# NV32F100 register map
File version: 1.6
Registers are 32-bit, read-write, reset 0x0 unless marked. A register's access mark holds for its fields unless they carry their own. Offsets are from the block's base; [hi:lo] are bit positions; {n}, {i} and the like mark numbered series; 'fields as' and 'values as' point back to an identical list.

## SIM — System Integration Module
Base 0x40047000; register names take the prefix SIM_
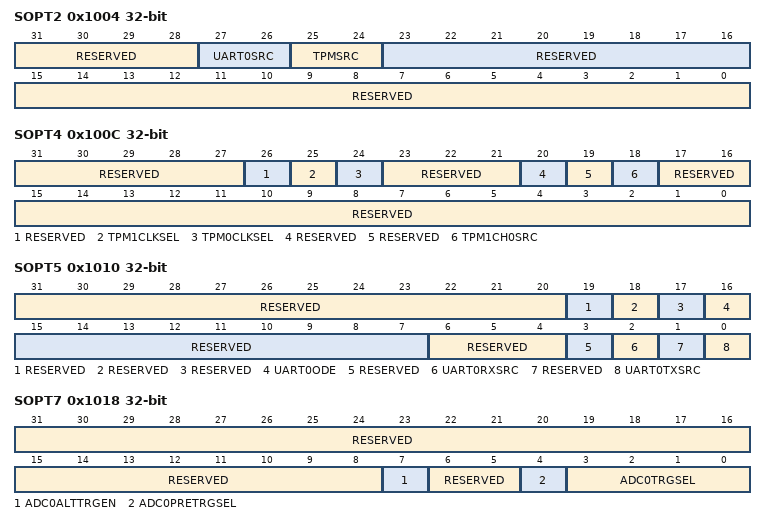
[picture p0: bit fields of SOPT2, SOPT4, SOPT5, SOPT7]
0x1004 SOPT2 — System Options Register 2
  [31:28] RESERVED ro
  [27:26] UART0SRC — UART0 clock source select
    0=Clock disabled; 1=MCGFLLCLK clock; 2=OSCERCLK clock; 3=MCGIRCLK clock
  [25:24] TPMSRC — TPM clock source select
    values as UART0SRC
  [23:16] RESERVED ro
  [15:0] RESERVED ro
0x100C SOPT4 — System Options Register 4
  [31:27] RESERVED ro
  [26] RESERVED ro
  [25] TPM1CLKSEL — TPM1 External Clock Pin Select
    0=TPM1 external clock driven by TPM_CLKIN0 pin; 1=TPM1 external clock driven by TPM_CLKIN1 pin
  [24] TPM0CLKSEL — TPM0 External Clock Pin Select
    0=TPM0 external clock driven by TPM_CLKIN0 pin; 1=TPM0 external clock driven by TPM_CLKIN1 pin
  [23:21] RESERVED ro
  [20] RESERVED ro
  [19] RESERVED ro
  [18] TPM1CH0SRC — TPM1 channel 0 input capture source select
    0=TPM1_CH0 signal; 1=CMP0 output
  [17:0] RESERVED ro
0x1010 SOPT5 — System Options Register 5
  [31:20] RESERVED ro
  [19] RESERVED ro
  [18] RESERVED ro
  [17] RESERVED ro
  [16] UART0ODE — UART0 Open Drain Enable
    0=Open drain is disabled on UART0; 1=Open drain is enabled on UART0
  [15:7] RESERVED ro
  [6:4] RESERVED ro
  [3] RESERVED ro
  [2] UART0RXSRC — UART0 receive data source select
    0=UART0_RX pin; 1=CMP0 output
  [1] RESERVED ro
  [0] UART0TXSRC — UART0 transmit data source select
    0=UART0_TX pin; 1=UART0_TX pin modulated with TPM1 channel 0 output
0x1018 SOPT7 — System Options Register 7
  [31:8] RESERVED ro
  [7] ADC0ALTTRGEN — ADC0 alternate trigger enable
    0=TPM1 channel 0 (A) and channel 1 (B) triggers selected for ADC0; 1=Alternate trigger selected for ADC0
  [6:5] RESERVED ro
  [4] ADC0PRETRGSEL — ADC0 pretrigger select
    0=Pre-trigger A; 1=Pre-trigger B
  [3:0] ADC0TRGSEL — ADC0 trigger select
    0=External trigger pin input (EXTRG_IN); 1=CMP0 output; 8=TPM0 overflow; 9=TPM1 overflow; 14=LPTMR0 trigger
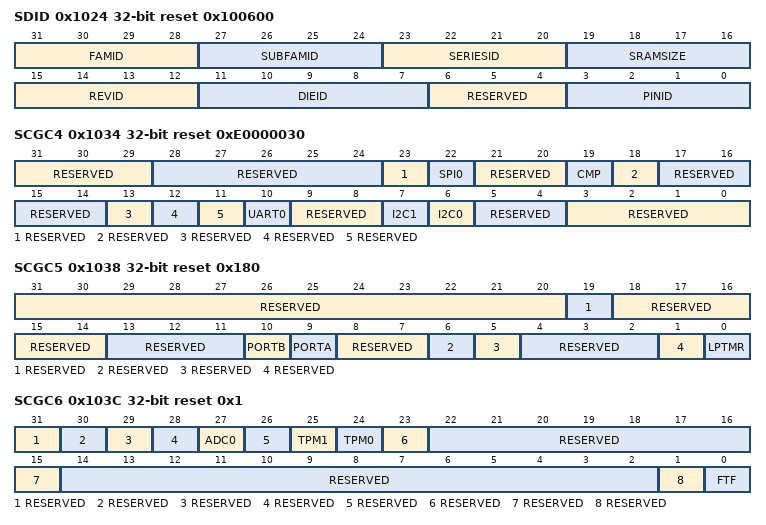
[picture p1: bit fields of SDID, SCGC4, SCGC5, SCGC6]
0x1024 SDID ro reset 0x100600 — System Device Identification Register
  [31:28] FAMID — Kinetis family ID
    0=KL0x Family (low end); 1=KL1x Family (basic); 2=KL2x Family (USB); 3=KL3x Family (Segment LCD); 4=KL4x Family (USB and Segment LCD)
  [27:24] SUBFAMID — Kinetis Sub-Family ID
    2=KLx2 Subfamily (low end); 4=KLx4 Subfamily (basic analog); 5=KLx5 Subfamily (advanced analog); 6=KLx6 Subfamily (advanced analog with I2S)
  [23:20] SERIESID — Kinetis Series ID
    1=KL family
  [19:16] SRAMSIZE — System SRAM Size
    0=0.5 KB; 1=1 KB; 2=2 KB; 3=4 KB; 4=8 KB; 5=16 KB; 6=32 KB; 7=64 KB
  [15:12] REVID — Device revision number
  [11:7] DIEID — Device die number
  [6:4] RESERVED
  [3:0] PINID — Pincount identification
    0=16-pin; 1=24-pin; 2=32-pin; 4=48-pin; 5=64-pin; 6=80-pin; 8=100-pin
0x1034 SCGC4 reset 0xE0000030 — System Clock Gating Control Register 4
  [31:29] RESERVED ro
  [28:24] RESERVED ro
  [23] RESERVED ro
  [22] SPI0 — SPI0 Clock Gate Control
    0=Clock disabled; 1=Clock enabled
  [21:20] RESERVED ro
  [19] CMP — Comparator Clock Gate Control
    0=Clock disabled; 1=Clock enabled
  [18] RESERVED ro
  [17:14] RESERVED ro
  [13] RESERVED ro
  [12] RESERVED ro
  [11] RESERVED ro
  [10] UART0 — UART0 Clock Gate Control
    0=Clock disabled; 1=Clock enabled
  [9:8] RESERVED ro
  [7] I2C1 — I2C1 Clock Gate Control
    0=Clock disabled; 1=Clock enabled
  [6] I2C0 — I2C0 Clock Gate Control
    0=Clock disabled; 1=Clock enabled
  [5:4] RESERVED ro
  [3:0] RESERVED ro
0x1038 SCGC5 reset 0x180 — System Clock Gating Control Register 5
  [31:20] RESERVED ro
  [19] RESERVED ro
  [18:14] RESERVED ro
  [13:11] RESERVED ro
  [10] PORTB — Port B Clock Gate Control
    0=Clock disabled; 1=Clock enabled
  [9] PORTA — Port A Clock Gate Control
    0=Clock disabled; 1=Clock enabled
  [8:7] RESERVED ro
  [6] RESERVED ro
  [5] RESERVED ro
  [4:2] RESERVED ro
  [1] RESERVED ro
  [0] LPTMR — Low Power Timer Access Control
    0=Access disabled; 1=Access enabled
0x103C SCGC6 reset 0x1 — System Clock Gating Control Register 6
  [31] RESERVED ro
  [30] RESERVED ro
  [29] RESERVED ro
  [28] RESERVED ro
  [27] ADC0 — ADC0 Clock Gate Control
    0=Clock disabled; 1=Clock enabled
  [26] RESERVED ro
  [25] TPM1 — TPM1 Clock Gate Control
    0=Clock disabled; 1=Clock enabled
  [24] TPM0 — TPM0 Clock Gate Control
    0=Clock disabled; 1=Clock enabled
  [23] RESERVED ro
  [22:16] RESERVED ro
  [15] RESERVED ro
  [14:2] RESERVED ro
  [1] RESERVED ro
  [0] FTF — Flash Memory Clock Gate Control
    0=Clock disabled; 1=Clock enabled
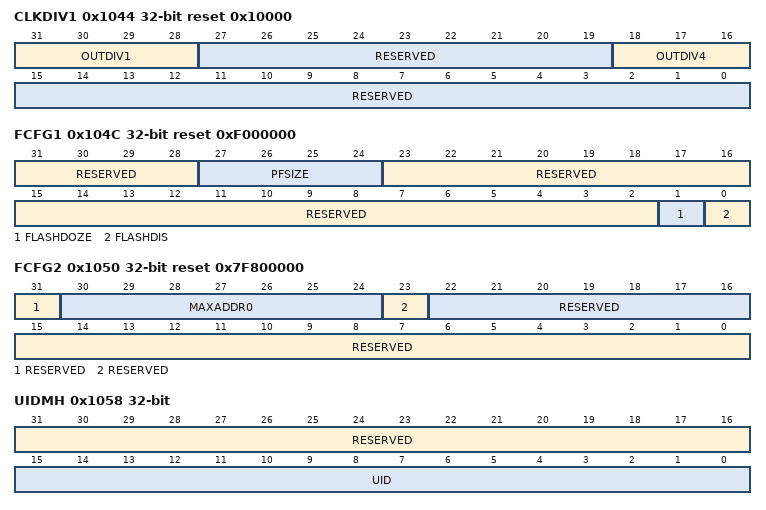
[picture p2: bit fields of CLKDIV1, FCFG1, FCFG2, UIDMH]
0x1044 CLKDIV1 reset 0x10000 — System Clock Divider Register 1
  [31:28] OUTDIV1 — Clock 1 output divider value
    {v}=Divide-by-{v+1} (v=0..15)
  [27:19] RESERVED ro
  [18:16] OUTDIV4 — Clock 4 output divider value
    {v}=Divide-by-{v+1} (v=0..7)
  [15:0] RESERVED ro
0x104C FCFG1 reset 0xF000000 — Flash Configuration Register 1
  [31:28] RESERVED ro
  [27:24] PFSIZE ro — Program flash size
    0=8 KB of program flash memory, 0.25 KB protection region; 1=16 KB of program flash memory, 0.5 KB protection region; 3=32 KB of program flash memory, 1 KB protection region; 5=64 KB of program flash memory, 2 KB protection region; 7=128 KB of program flash memory, 4 KB protection region; 9=256 KB of program flash memory, 8 KB protection region; 15=32 KB of program flash memory, 1 KB protection region
  [23:2] RESERVED ro
  [1] FLASHDOZE
    0=Flash remains enabled during Doze mode; 1=Flash is disabled for the duration of Doze mode
  [0] FLASHDIS — Flash Disable
    0=Flash is enabled; 1=Flash is disabled
0x1050 FCFG2 ro reset 0x7F800000 — Flash Configuration Register 2
  [31] RESERVED
  [30:24] MAXADDR0 — Max address block
  [23] RESERVED
  [22:16] RESERVED
  [15:0] RESERVED
0x1058 UIDMH ro — Unique Identification Register Mid-High
  [31:16] RESERVED
  [15:0] UID — Unique Identification
0x105C UIDML ro — Unique Identification Register Mid Low
  [31:0] UID — Unique Identification
0x1060 UIDL ro — Unique Identification Register Low
  [31:0] UID — Unique Identification
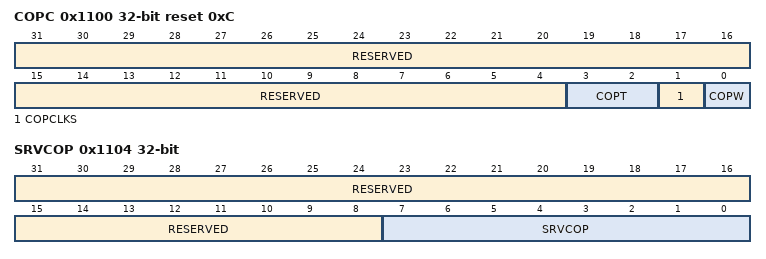
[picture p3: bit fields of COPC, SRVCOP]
0x1100 COPC reset 0xC — COP Control Register
  [31:4] RESERVED ro
  [3:2] COPT — COP Watchdog Timeout
    0=COP disabled; 1=COP timeout after 25 LPO cycles or 213 bus clock cycles; 2=COP timeout after 28 LPO cycles or 216 bus clock cycles; 3=COP timeout after 210 LPO cycles or 218 bus clock cycles
  [1] COPCLKS — COP Clock Select
    0=Internal 1 kHz clock is source to COP; 1=Bus clock is source to COP
  [0] COPW — COP windowed mode
    0=Normal mode; 1=Windowed mode
0x1104 SRVCOP wo — Service COP Register
  [31:8] RESERVED
  [7:0] SRVCOP — Sevice COP Register
